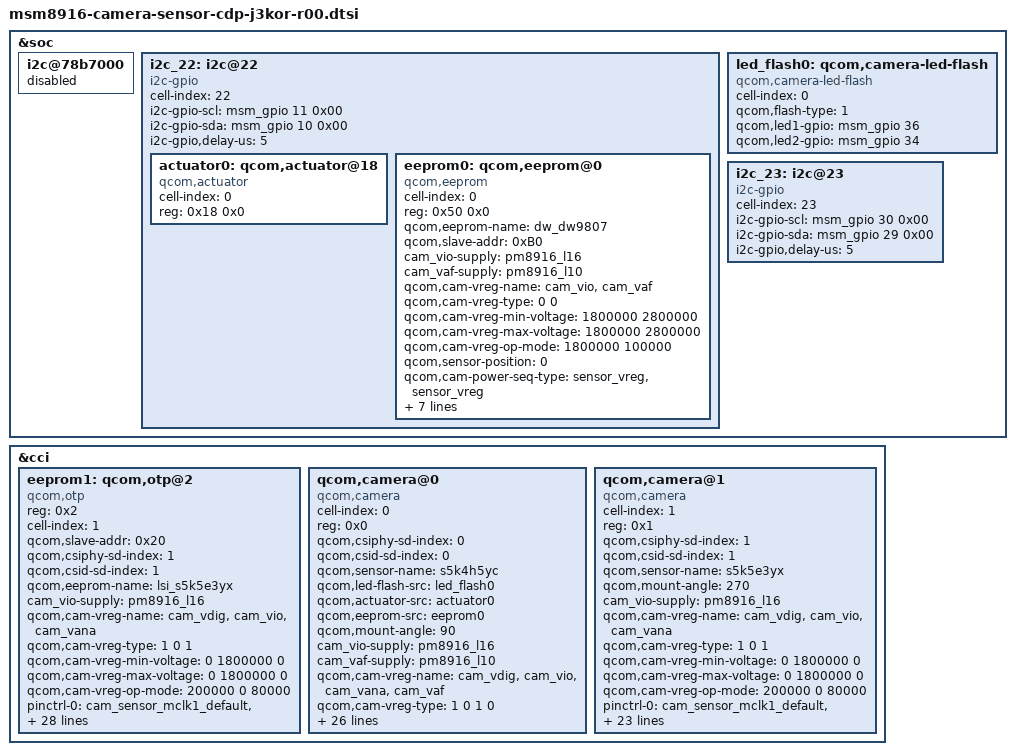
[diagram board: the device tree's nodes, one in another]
/*
 * Copyright (c) 2014, The Linux Foundation. All rights reserved.
 *
 * This program is free software; you can redistribute it and/or modify
 * it under the terms of the GNU General Public License version 2 and
 * only version 2 as published by the Free Software Foundation.
 *
 * This program is distributed in the hope that it will be useful,
 * but WITHOUT ANY WARRANTY; without even the implied warranty of
 * MERCHANTABILITY or FITNESS FOR A PARTICULAR PURPOSE.  See the
 * GNU General Public License for more details.
 */


&soc {
	i2c@78b7000 { /* BLSP1 QUP3 */
		status = "disable";
	};
	i2c_22: i2c@22 {
		cell-index = <22>;
		compatible = "i2c-gpio";
		i2c-gpio-scl = <&msm_gpio 11 0x00>;
		i2c-gpio-sda = <&msm_gpio 10 0x00>;
		i2c-gpio,delay-us = <5>;

		actuator0: qcom,actuator@18 {
			compatible = "qcom,actuator";
			cell-index = <0>;
			reg = <0x18 0x0>;
		};

		eeprom0: qcom,eeprom@0 {
		compatible = "qcom,eeprom";
		cell-index = <0>;
		reg = <0x50 0x0>;
		qcom,eeprom-name = "dw_dw9807";
		qcom,slave-addr = <0xB0>;
		cam_vio-supply = <&pm8916_l16>;
		cam_vaf-supply = <&pm8916_l10>;
		qcom,cam-vreg-name = "cam_vio", "cam_vaf";
		qcom,cam-vreg-type = <0 0>;
		qcom,cam-vreg-min-voltage = <1800000 2800000>;
		qcom,cam-vreg-max-voltage = <1800000 2800000>;
		qcom,cam-vreg-op-mode = <1800000 100000>;
		qcom,sensor-position = <0>;
		pinctrl-names = "eeprom_default", "eeprom_suspend";
		/*pinctrl-0 = <&cam_sensor_eeprom_default>;*/
		/*pinctrl-1 = <&cam_sensor_eeprom_sleep>;*/
		qcom,cam-power-seq-type = "sensor_vreg", "sensor_vreg";
		qcom,cam-power-seq-val = "cam_vio", "cam_vaf";
		qcom,cam-power-seq-cfg-val = <1 1>;
		qcom,cam-power-seq-delay =   <1 1>;
		qcom,cal-num-blocks = <1>;
		qcom,cal-page0 = <0 0 0 0 0 0>;
		qcom,cal-poll0 = <0 0 0 0 0 0>;
		qcom,cal-mem0 = <0x1200 0x00 2 0 1 0>;
		status = "ok";
		};
	};

	led_flash0: qcom,camera-led-flash {
		cell-index = <0>;
		compatible = "qcom,camera-led-flash";
		qcom,flash-type = <1>;
		qcom,led1-gpio = <&msm_gpio 36 0x00>;
		qcom,led2-gpio = <&msm_gpio 34 0x00>;
	};

	i2c_23: i2c@23 {
		cell-index = <23>;
		compatible = "i2c-gpio";
		i2c-gpio-scl = <&msm_gpio 30 0x00>;
		i2c-gpio-sda = <&msm_gpio 29 0x00>;
		i2c-gpio,delay-us = <5>;
	};
};

&cci {
	eeprom1: qcom,otp@2 {
		compatible = "qcom,otp";
		reg = <0x2>;
		cell-index = <1>;
		qcom,slave-addr = <0x20>;
		qcom,csiphy-sd-index = <1>;
		qcom,csid-sd-index = <1>;
		qcom,eeprom-name = "lsi_s5k5e3yx";
		cam_vio-supply = <&pm8916_l16>;
		qcom,cam-vreg-name = "cam_vdig", "cam_vio", "cam_vana";
		qcom,cam-vreg-type = <1 0 1>;
		qcom,cam-vreg-min-voltage = <0 1800000 0>;
		qcom,cam-vreg-max-voltage = <0 1800000 0>;
		qcom,cam-vreg-op-mode = <200000 0 80000>;
		pinctrl-names = "cam_default", "cam_suspend";
		pinctrl-0 = <&cam_sensor_mclk1_default &cam_sensor_front_default>;
		pinctrl-1 = <&cam_sensor_mclk1_sleep &cam_sensor_front_sleep>;
		gpios = <&msm_gpio 27 0>,
			  <&msm_gpio 28 0>;
		qcom,gpio-reset = <1>;
		qcom,gpio-req-tbl-num = <0 1>;
		qcom,gpio-req-tbl-flags = <1 0>;
		qcom,gpio-req-tbl-label = "CAMIF_MCLK",
			"CAM_RESET";
		qcom,sensor-position = <1>;
		qcom,sensor-mode = <0>;
		qcom,cci-master = <0>;
		qcom,cam-power-seq-type = "sensor_gpio", "sensor_vreg", "sensor_vreg", "sensor_vreg", "sensor_gpio", "sensor_gpio", "sensor_clk", "sensor_i2c_mux";
		qcom,cam-power-seq-val = "sensor_gpio_vdig", "cam_vana", "cam_vdig", "cam_vio", "sensor_gpio_reset", "sensor_gpio_reset", "sensor_cam_mclk", "none";
		qcom,cam-power-seq-cfg-val = <1 1 1 1 0 1 26022000 0>;
		qcom,cam-power-seq-delay =   <1 1 1 1 2 30 1 5>;
		status = "ok";
		clocks = <&clock_gcc clk_mclk1_clk_src>,
			   <&clock_gcc clk_gcc_camss_mclk1_clk>;
		clock-names = "cam_src_clk", "cam_clk";
		qcom,num-blocks = <1>;
		qcom,page0 = <0 0 0 0 0 0>;
		qcom,poll0 = <0 0 0 0 0 0>;
		qcom,mem0 = <0x3A 0x00 2 0 1 0>;
	};

	qcom,camera@0 {
		cell-index = <0>;
		compatible = "qcom,camera";
		reg = <0x0>;
		qcom,csiphy-sd-index = <0>;
		qcom,csid-sd-index = <0>;
		qcom,sensor-name = "s5k4h5yc";
		qcom,led-flash-src =<&led_flash0>;
		qcom,actuator-src = <&actuator0>;
		qcom,eeprom-src = <&eeprom0>;
		qcom,mount-angle = <90>;
		cam_vio-supply = <&pm8916_l16>;
		cam_vaf-supply = <&pm8916_l10>;
		qcom,cam-vreg-name = "cam_vdig", "cam_vio", "cam_vana",
			"cam_vaf";
		qcom,cam-vreg-type = <1 0 1 0>;
		qcom,cam-vreg-min-voltage = <0 1800000 0 2800000>;
		qcom,cam-vreg-max-voltage = <0 1800000 0 2800000>;
		qcom,cam-vreg-op-mode = <200000 0 80000 100000>;
		pinctrl-names = "cam_default", "cam_suspend";
		pinctrl-0 = <&cam_sensor_mclk0_default &cam_core_en_default &cam_sensor_rear_default>;/*&cam_sensor_eeprom_default*/
		pinctrl-1 = <&cam_sensor_mclk0_sleep &cam_core_en_sleep &cam_sensor_rear_sleep>;/*&cam_sensor_eeprom_sleep &cam_eepwp_sleep>;*/
		gpios = <&msm_gpio 26 0>,
				<&msm_gpio 33 0>,
				<&msm_gpio 35 0>;
		qcom,gpio-vdig = <1>;
		qcom,gpio-reset = <2>;
		qcom,gpio-req-tbl-num = <0 1 2>;
		qcom,gpio-req-tbl-flags = <1 0 0>;
		qcom,gpio-req-tbl-label = "CAMIF_MCLK",
			"CAM_VDIG",
			"CAM_RESET1";
		qcom,sensor-position = <0>;
		qcom,sensor-mode = <0>;
		qcom,cci-master = <0>;
		status = "ok";
		clocks = <&clock_gcc clk_mclk0_clk_src>,
			   <&clock_gcc clk_gcc_camss_mclk0_clk>;
		clock-names = "cam_src_clk", "cam_clk";
		cam,isp = <0>;			// 0 : INT , 1 : EXT , 2 : SOC
		cam,cal_memory = <2>;		// 0 : N , 1 : FROM , 2 : EEPROM , 3 : OTP
		cam,read_version = <0>;		// 0 : SYSFS , 1 : CAMON
		cam,core_voltage = <0>;		// 0 : N , 1 : Y
		cam,upgrade = <0>;			// 0 : N , 1 : SYSFS , 2 : CAMON
		cam,companion_chip = <0>;		// 0 : N , 1 : Y
		cam,ois = <0>;			// 0 : N , 1 : Y
	};

	qcom,camera@1 {
		cell-index = <1>;
		compatible = "qcom,camera";
		reg = <0x1>;
		qcom,csiphy-sd-index = <1>;
		qcom,csid-sd-index = <1>;
		qcom,sensor-name = "s5k5e3yx";
		/*qcom,eeprom-src = <&eeprom1>;*/
		qcom,mount-angle = <270>;
		cam_vio-supply = <&pm8916_l16>;
		qcom,cam-vreg-name = "cam_vdig", "cam_vio", "cam_vana";
		qcom,cam-vreg-type = <1 0 1>;
		qcom,cam-vreg-min-voltage = <0 1800000 0>;
		qcom,cam-vreg-max-voltage = <0 1800000 0>;
		qcom,cam-vreg-op-mode = <200000 0 80000>;
		pinctrl-names = "cam_default", "cam_suspend";
		pinctrl-0 = <&cam_sensor_mclk1_default &cam_core_en_default &cam_sensor_front_default>;
		pinctrl-1 = <&cam_sensor_mclk1_sleep &cam_core_en_sleep &cam_sensor_front_sleep>;
		gpios = <&msm_gpio 27 0>,
				<&msm_gpio 33 0>,
			  <&msm_gpio 28 0>;
		qcom,gpio-vdig = <1>;
		qcom,gpio-reset = <2>;
		qcom,gpio-req-tbl-num = <0 1 2>;
		qcom,gpio-req-tbl-flags = <1 0 0>;
		qcom,gpio-req-tbl-label = "CAMIF_MCLK",
			"CAM_VDIG",
			"CAM_RESET";
		qcom,sensor-position = <1>;
		qcom,sensor-mode = <0>;
		qcom,cci-master = <0>;
		status = "ok";
		clocks = <&clock_gcc clk_mclk1_clk_src>,
			   <&clock_gcc clk_gcc_camss_mclk1_clk>;
		clock-names = "cam_src_clk", "cam_clk";
		cam,isp = <0>;			// 0 : INT , 1 : EXT , 2 : SOC
		cam,cal_memory = <0>;		// 0 : N , 1 : FROM , 2 : EEPROM , 3 : OTP
		cam,read_version = <0>;		// 0 : SYSFS , 1 : CAMON
		cam,core_voltage = <0>;		// 0 : N , 1 : Y
		cam,upgrade = <0>;			// 0 : N , 1 : SYSFS , 2 : CAMON
		cam,companion_chip = <0>;		// 0 : N , 1 : Y
		cam,ois = <0>;			// 0 : N , 1 : Y
	};
};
